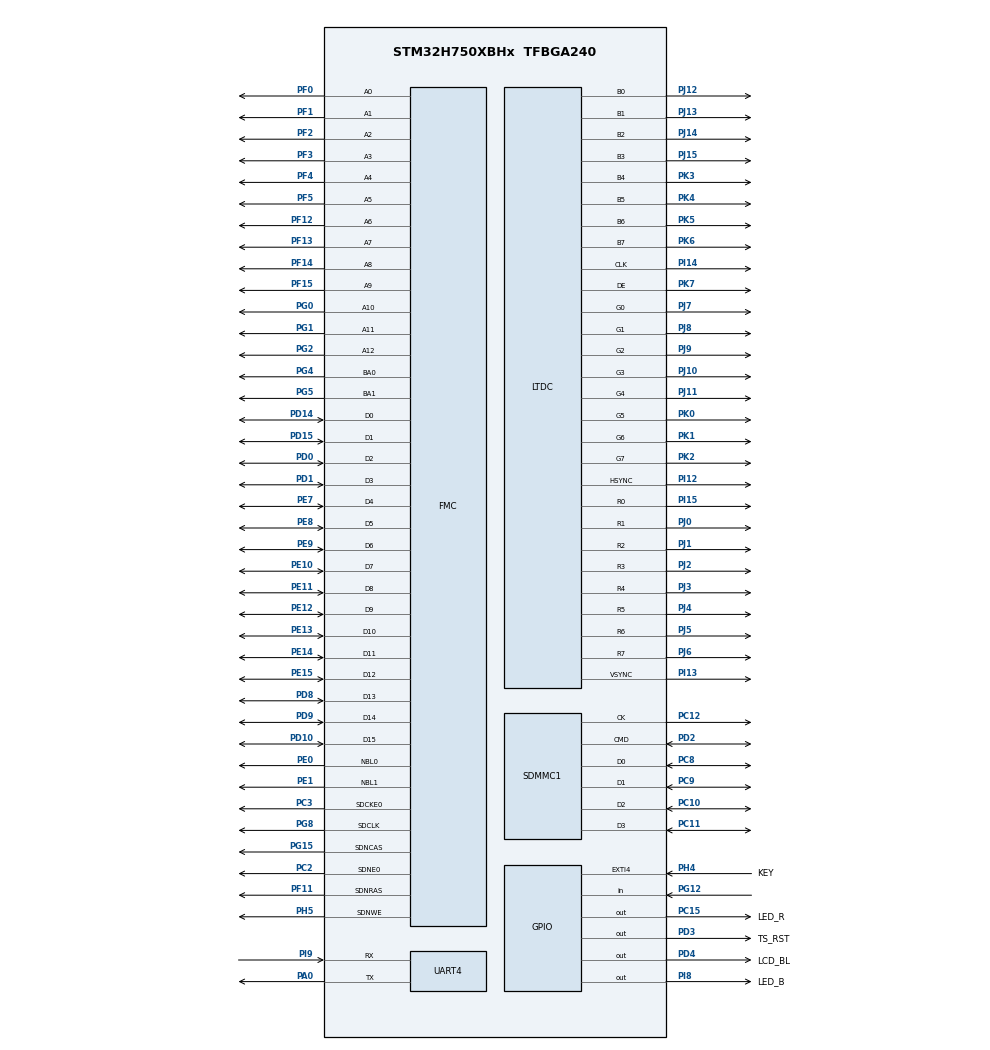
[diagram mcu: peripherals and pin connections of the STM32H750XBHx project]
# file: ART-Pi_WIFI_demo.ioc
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CORTEX_M7.AccessPermission-Cortex_Memory_Protection_Unit_Region0_Settings=MPU_REGION_FULL_ACCESS
CORTEX_M7.AccessPermission-Cortex_Memory_Protection_Unit_Region1_Settings=MPU_REGION_FULL_ACCESS
CORTEX_M7.AccessPermission-Cortex_Memory_Protection_Unit_Region2_Settings=MPU_REGION_FULL_ACCESS
CORTEX_M7.AccessPermission_Spec=MPU_REGION_FULL_ACCESS
CORTEX_M7.BaseAddress-Cortex_Memory_Protection_Unit_Region0_Settings=0x90000000
CORTEX_M7.BaseAddress-Cortex_Memory_Protection_Unit_Region1_Settings=0xC0000000
CORTEX_M7.BaseAddress-Cortex_Memory_Protection_Unit_Region2_Settings=0x24000000
CORTEX_M7.BaseAddress_Spec=0x90000000
CORTEX_M7.CPU_DCache=Enabled
CORTEX_M7.CPU_ICache=Enabled
CORTEX_M7.Enable-Cortex_Memory_Protection_Unit_Region0_Settings=MPU_REGION_ENABLE
CORTEX_M7.Enable-Cortex_Memory_Protection_Unit_Region1_Settings=MPU_REGION_ENABLE
CORTEX_M7.Enable-Cortex_Memory_Protection_Unit_Region2_Settings=MPU_REGION_ENABLE
CORTEX_M7.IsBufferable-Cortex_Memory_Protection_Unit_Region0_Settings=MPU_ACCESS_BUFFERABLE
CORTEX_M7.IsBufferable-Cortex_Memory_Protection_Unit_Region2_Settings=MPU_ACCESS_BUFFERABLE
CORTEX_M7.IsBufferable_Spec=MPU_ACCESS_BUFFERABLE
CORTEX_M7.IsCacheable-Cortex_Memory_Protection_Unit_Region0_Settings=MPU_ACCESS_CACHEABLE
CORTEX_M7.IsCacheable-Cortex_Memory_Protection_Unit_Region1_Settings=MPU_ACCESS_CACHEABLE
CORTEX_M7.IsCacheable-Cortex_Memory_Protection_Unit_Region2_Settings=MPU_ACCESS_CACHEABLE
CORTEX_M7.IsCacheable_Spec=MPU_ACCESS_CACHEABLE
CORTEX_M7.IsShareable_Spec=MPU_ACCESS_NOT_SHAREABLE
CORTEX_M7.MPU_Control=MPU_PRIVILEGED_DEFAULT
CORTEX_M7.Size-Cortex_Memory_Protection_Unit_Region0_Settings=MPU_REGION_SIZE_8MB
CORTEX_M7.Size-Cortex_Memory_Protection_Unit_Region1_Settings=MPU_REGION_SIZE_32MB
CORTEX_M7.Size-Cortex_Memory_Protection_Unit_Region2_Settings=MPU_REGION_SIZE_512KB
CORTEX_M7.Size_Spec=MPU_REGION_SIZE_8MB
CORTEX_M7.TypeExtField-Cortex_Memory_Protection_Unit_Region0_Settings=MPU_TEX_LEVEL1
CORTEX_M7.TypeExtField-Cortex_Memory_Protection_Unit_Region2_Settings=MPU_TEX_LEVEL1
CORTEX_M7.TypeExtField_Spec=MPU_TEX_LEVEL1
DMA2D.ColorMode=DMA2D_OUTPUT_RGB565
DMA2D.Mode=DMA2D_M2M
Dma.Request0=UART4_RX
Dma.Request1=UART4_TX
Dma.UART4_RX.0.Direction=DMA_PERIPH_TO_MEMORY
Dma.UART4_RX.0.EventEnable=DISABLE
Dma.UART4_RX.0.FIFOMode=DMA_FIFOMODE_DISABLE
Dma.UART4_RX.0.Instance=DMA1_Stream0
Dma.UART4_RX.0.MemDataAlignment=DMA_MDATAALIGN_BYTE
Dma.UART4_RX.0.MemInc=DMA_MINC_ENABLE
Dma.UART4_RX.0.Mode=DMA_NORMAL
Dma.UART4_RX.0.PeriphDataAlignment=DMA_PDATAALIGN_BYTE
Dma.UART4_RX.0.PeriphInc=DMA_PINC_DISABLE
Dma.UART4_RX.0.Polarity=HAL_DMAMUX_REQ_GEN_RISING
Dma.UART4_RX.0.Priority=DMA_PRIORITY_LOW
Dma.UART4_RX.0.RequestNumber=1
Dma.UART4_RX.0.SignalID=NONE
Dma.UART4_RX.0.SyncEnable=DISABLE
Dma.UART4_RX.0.SyncPolarity=HAL_DMAMUX_SYNC_NO_EVENT
Dma.UART4_RX.0.SyncRequestNumber=1
Dma.UART4_RX.0.SyncSignalID=NONE
Dma.UART4_TX.1.Direction=DMA_MEMORY_TO_PERIPH
Dma.UART4_TX.1.EventEnable=DISABLE
Dma.UART4_TX.1.FIFOMode=DMA_FIFOMODE_DISABLE
Dma.UART4_TX.1.Instance=DMA1_Stream1
Dma.UART4_TX.1.MemDataAlignment=DMA_MDATAALIGN_BYTE
Dma.UART4_TX.1.MemInc=DMA_MINC_ENABLE
Dma.UART4_TX.1.Mode=DMA_NORMAL
Dma.UART4_TX.1.PeriphDataAlignment=DMA_PDATAALIGN_BYTE
Dma.UART4_TX.1.PeriphInc=DMA_PINC_DISABLE
Dma.UART4_TX.1.Polarity=HAL_DMAMUX_REQ_GEN_RISING
Dma.UART4_TX.1.Priority=DMA_PRIORITY_LOW
Dma.UART4_TX.1.RequestNumber=1
Dma.UART4_TX.1.SignalID=NONE
Dma.UART4_TX.1.SyncEnable=DISABLE
Dma.UART4_TX.1.SyncPolarity=HAL_DMAMUX_SYNC_NO_EVENT
Dma.UART4_TX.1.SyncRequestNumber=1
Dma.UART4_TX.1.SyncSignalID=NONE
FATFS._CODE_PAGE=936
FATFS._FS_EXFAT=1
FATFS._MAX_SS=4096
FATFS._MIN_SS=512
FATFS._USE_LFN=2
FMC.CASLatency1=FMC_SDRAM_CAS_LATENCY_3
FMC.ColumnBitsNumber1=FMC_SDRAM_COLUMN_BITS_NUM_9
FMC.ExitSelfRefreshDelay1=8
FMC.LoadToActiveDelay1=2
FMC.RCDDelay1=2
FMC.RPDelay1=2
FMC.ReadBurst1=FMC_SDRAM_RBURST_ENABLE
FMC.ReadPipeDelay1=FMC_SDRAM_RPIPE_DELAY_1
FMC.RowCycleDelay1=7
FMC.SDClockPeriod1=FMC_SDRAM_CLOCK_PERIOD_2
FMC.SelfRefreshTime1=6
FMC.WriteRecoveryTime1=5
FREERTOS.Tasks01=defaultTask,-3,1024,StartDefaultTask,Default,NULL,Dynamic,NULL,NULL;Debug_task,0,1024,debug_thread,Default,NULL,Dynamic,NULL,NULL;lvgl_task,-2,1024,lvgl_thread,Default,NULL,Dynamic,NULL,NULL;flie_task,0,1024,flie_thread,Default,NULL,Dynamic,NULL,NULL;key_task,-2,512,key_thread,Default,NULL,Dynamic,NULL,NULL;led_task,-2,512,led_thread,Default,NULL,Dynamic,NULL,NULL;main_task,-3,2048,main_thread,Default,NULL,Dynamic,NULL,NULL
FREERTOS.configENABLE_FPU=1
FREERTOS.configTOTAL_HEAP_SIZE=40000
FREERTOS.configUSE_NEWLIB_REENTRANT=1
FREERTOS.configUSE_TICK_HOOK=1
LTDC.ActiveH=600
LTDC.ActiveW=1024
LTDC.Alpha_L0=255
LTDC.Blue_L0=255
LTDC.FBStartAdress_L0=0xC0000000
LTDC.Green_L0=255
LTDC.HBP=140
LTDC.HFP=160
LTDC.HSync=20
LTDC.ImageHeight_L0=600
LTDC.ImageWidth_L0=1024
LTDC.Layers=0
LTDC.PixelFormat_L0=LTDC_PIXEL_FORMAT_RGB565
LTDC.Red_L0=255
LTDC.VBP=20
LTDC.VFP=12
LTDC.VSync=3
LTDC.WindowX1_L0=1024
LTDC.WindowY1_L0=600
Mcu.Family=STM32H7
Mcu.Name=STM32H750XBHx
Mcu.Package=TFBGA240
Mcu.UserConstants=LTDC_BUFF_ADDR,0XC0000000
NVIC.DMA1_Stream0_IRQn=true\:5\:0\:true\:false\:true\:true\:false\:true\:true
NVIC.DMA1_Stream1_IRQn=true\:5\:0\:true\:false\:true\:true\:false\:true\:true
NVIC.DMA2D_IRQn=true\:5\:0\:false\:false\:true\:true\:true\:true\:true
NVIC.EXTI4_IRQn=true\:5\:0\:true\:false\:true\:true\:true\:true\:true
NVIC.LTDC_IRQn=true\:5\:0\:false\:false\:true\:true\:true\:true\:true
NVIC.PriorityGroup=NVIC_PRIORITYGROUP_4
NVIC.SDMMC1_IRQn=true\:5\:0\:false\:false\:true\:true\:true\:true\:true
NVIC.TIM6_DAC_IRQn=true\:15\:0\:false\:false\:true\:false\:false\:true\:true
NVIC.TimeBase=TIM6_DAC_IRQn
NVIC.TimeBaseIP=TIM6
NVIC.UART4_IRQn=true\:5\:0\:false\:false\:true\:true\:true\:true\:true
PA0.Mode=Asynchronous
PA0.Signal=UART4_TX
PA13\ (JTMS/SWDIO).Mode=Serial_Wire
PA13\ (JTMS/SWDIO).Signal=DEBUG_JTMS-SWDIO
PA14\ (JTCK/SWCLK).Mode=Serial_Wire
PA14\ (JTCK/SWCLK).Signal=DEBUG_JTCK-SWCLK
PB6.GPIO_Pu=GPIO_PULLUP
PB6.GPIO_Speed=GPIO_SPEED_FREQ_VERY_HIGH
PB6.Signal=I2C1_SCL
PB7.GPIO_Pu=GPIO_PULLUP
PB7.GPIO_Speed=GPIO_SPEED_FREQ_VERY_HIGH
PB7.Signal=I2C1_SDA
PB8.GPIO_Pu=GPIO_PULLUP
PB8.GPIO_Speed=GPIO_SPEED_FREQ_VERY_HIGH
PB8.Signal=I2C4_SCL
PB9.GPIO_Pu=GPIO_PULLUP
PB9.GPIO_Speed=GPIO_SPEED_FREQ_VERY_HIGH
PB9.Signal=I2C4_SDA
PC10.GPIO_PuPd=GPIO_PULLUP
PC10.Mode=SD_4_bits_Wide_bus
PC10.Signal=SDMMC1_D2
PC11.GPIO_PuPd=GPIO_PULLUP
PC11.Mode=SD_4_bits_Wide_bus
PC11.Signal=SDMMC1_D3
PC12.Mode=SD_4_bits_Wide_bus
PC12.Signal=SDMMC1_CK
PC15-OSC32_OUT\ (OSC32_OUT).GPIO_Label=LED_R
PC15-OSC32_OUT\ (OSC32_OUT).Signal=GPIO_Output
PC2.Mode=SdramChipSelect1_1
PC2.Signal=FMC_SDNE0
PC3.Mode=SdramChipSelect1_1
PC3.Signal=FMC_SDCKE0
PC8.GPIO_PuPd=GPIO_PULLUP
PC8.Mode=SD_4_bits_Wide_bus
PC8.Signal=SDMMC1_D0
PC9.GPIO_PuPd=GPIO_PULLUP
PC9.Mode=SD_4_bits_Wide_bus
PC9.Signal=SDMMC1_D1
PD0.Signal=FMC_D2_DA2
PD1.Signal=FMC_D3_DA3
PD10.Signal=FMC_D15_DA15
PD14.Signal=FMC_D0_DA0
PD15.Signal=FMC_D1_DA1
PD2.GPIO_PuPd=GPIO_PULLUP
PD2.Mode=SD_4_bits_Wide_bus
PD2.Signal=SDMMC1_CMD
PD3.GPIO_Label=TS_RST
PD3.GPIO_Speed=GPIO_SPEED_FREQ_HIGH
PD3.Signal=GPIO_Output
PD4.GPIO_Label=LCD_BL
PD4.GPIO_Speed=GPIO_SPEED_FREQ_VERY_HIGH
PD4.Signal=GPIO_Output
PD8.Signal=FMC_D13_DA13
PD9.Signal=FMC_D14_DA14
PE0.Signal=FMC_NBL0
PE1.Signal=FMC_NBL1
PE10.Signal=FMC_D7_DA7
PE11.Signal=FMC_D8_DA8
PE12.Signal=FMC_D9_DA9
PE13.Signal=FMC_D10_DA10
PE14.Signal=FMC_D11_DA11
PE15.Signal=FMC_D12_DA12
PE7.Signal=FMC_D4_DA4
PE8.Signal=FMC_D5_DA5
PE9.Signal=FMC_D6_DA6
PF0.Signal=FMC_A0
PF1.Signal=FMC_A1
PF11.Signal=FMC_SDNRAS
PF12.Signal=FMC_A6
PF13.Signal=FMC_A7
PF14.Signal=FMC_A8
PF15.Signal=FMC_A9
PF2.Signal=FMC_A2
PF3.Signal=FMC_A3
PF4.Signal=FMC_A4
PF5.Signal=FMC_A5
PG0.Signal=FMC_A10
PG1.Signal=FMC_A11
PG12.GPIO_PuPd=GPIO_PULLUP
PG12.Signal=GPIO_Input
PG15.Signal=FMC_SDNCAS
PG2.Signal=FMC_A12
PG4.Signal=FMC_A14_BA0
PG5.Signal=FMC_A15_BA1
PG8.Signal=FMC_SDCLK
PH0-OSC_IN\ (PH0).Mode=HSE-External-Oscillator
PH0-OSC_IN\ (PH0).Signal=RCC_OSC_IN
PH1-OSC_OUT\ (PH1).Mode=HSE-External-Oscillator
PH1-OSC_OUT\ (PH1).Signal=RCC_OSC_OUT
PH4.GPIO_Label=KEY
PH4.GPIO_ModeDefaultEXTI=GPIO_MODE_IT_FALLING
PH4.GPIO_PuPd=GPIO_PULLUP
PH4.Signal=GPXTI4
PH5.Signal=FMC_SDNWE
PI12.GPIO_Speed=GPIO_SPEED_FREQ_VERY_HIGH
PI12.Mode=RGB888
PI12.Signal=LTDC_HSYNC
PI13.GPIO_Speed=GPIO_SPEED_FREQ_VERY_HIGH
PI13.Mode=RGB888
PI13.Signal=LTDC_VSYNC
PI14.GPIO_Speed=GPIO_SPEED_FREQ_VERY_HIGH
PI14.Mode=RGB888
PI14.Signal=LTDC_CLK
PI15.GPIO_Speed=GPIO_SPEED_FREQ_VERY_HIGH
PI15.Mode=RGB888
PI15.Signal=LTDC_R0
PI8.GPIO_Label=LED_B
PI8.Signal=GPIO_Output
PI9.Mode=Asynchronous
PI9.Signal=UART4_RX
PJ0.GPIO_Speed=GPIO_SPEED_FREQ_VERY_HIGH
PJ0.Mode=RGB888
PJ0.Signal=LTDC_R1
PJ1.GPIO_Speed=GPIO_SPEED_FREQ_VERY_HIGH
PJ1.Mode=RGB888
PJ1.Signal=LTDC_R2
PJ10.GPIO_Speed=GPIO_SPEED_FREQ_VERY_HIGH
PJ10.Mode=RGB888
PJ10.Signal=LTDC_G3
PJ11.GPIO_Speed=GPIO_SPEED_FREQ_VERY_HIGH
PJ11.Mode=RGB888
PJ11.Signal=LTDC_G4
PJ12.GPIO_Speed=GPIO_SPEED_FREQ_VERY_HIGH
PJ12.Mode=RGB888
PJ12.Signal=LTDC_B0
PJ13.GPIO_Speed=GPIO_SPEED_FREQ_VERY_HIGH
PJ13.Mode=RGB888
PJ13.Signal=LTDC_B1
PJ14.GPIO_Speed=GPIO_SPEED_FREQ_VERY_HIGH
PJ14.Mode=RGB888
PJ14.Signal=LTDC_B2
PJ15.GPIO_Speed=GPIO_SPEED_FREQ_VERY_HIGH
PJ15.Mode=RGB888
PJ15.Signal=LTDC_B3
PJ2.GPIO_Speed=GPIO_SPEED_FREQ_VERY_HIGH
PJ2.Mode=RGB888
PJ2.Signal=LTDC_R3
PJ3.GPIO_Speed=GPIO_SPEED_FREQ_VERY_HIGH
PJ3.Mode=RGB888
PJ3.Signal=LTDC_R4
PJ4.GPIO_Speed=GPIO_SPEED_FREQ_VERY_HIGH
PJ4.Mode=RGB888
PJ4.Signal=LTDC_R5
PJ5.GPIO_Speed=GPIO_SPEED_FREQ_VERY_HIGH
PJ5.Mode=RGB888
PJ5.Signal=LTDC_R6
PJ6.GPIO_Speed=GPIO_SPEED_FREQ_VERY_HIGH
PJ6.Mode=RGB888
PJ6.Signal=LTDC_R7
PJ7.GPIO_Speed=GPIO_SPEED_FREQ_VERY_HIGH
PJ7.Mode=RGB888
PJ7.Signal=LTDC_G0
PJ8.GPIO_Speed=GPIO_SPEED_FREQ_VERY_HIGH
PJ8.Mode=RGB888
PJ8.Signal=LTDC_G1
PJ9.GPIO_Speed=GPIO_SPEED_FREQ_VERY_HIGH
PJ9.Mode=RGB888
PJ9.Signal=LTDC_G2
PK0.GPIO_Speed=GPIO_SPEED_FREQ_VERY_HIGH
PK0.Mode=RGB888
PK0.Signal=LTDC_G5
PK1.GPIO_Speed=GPIO_SPEED_FREQ_VERY_HIGH
PK1.Mode=RGB888
PK1.Signal=LTDC_G6
PK2.GPIO_Speed=GPIO_SPEED_FREQ_VERY_HIGH
PK2.Mode=RGB888
PK2.Signal=LTDC_G7
PK3.GPIO_Speed=GPIO_SPEED_FREQ_VERY_HIGH
PK3.Mode=RGB888
PK3.Signal=LTDC_B4
PK4.GPIO_Speed=GPIO_SPEED_FREQ_VERY_HIGH
PK4.Mode=RGB888
PK4.Signal=LTDC_B5
PK5.GPIO_Speed=GPIO_SPEED_FREQ_VERY_HIGH
PK5.Mode=RGB888
PK5.Signal=LTDC_B6
PK6.GPIO_Speed=GPIO_SPEED_FREQ_VERY_HIGH
PK6.Mode=RGB888
PK6.Signal=LTDC_B7
PK7.GPIO_Speed=GPIO_SPEED_FREQ_VERY_HIGH
PK7.Mode=RGB888
PK7.Signal=LTDC_DE
ProjectManager.HeapSize=0xFFFF
ProjectManager.StackSize=0xFFFF
ProjectManager.TargetToolchain=STM32CubeIDE
RCC.ADCFreq_Value=50390625
RCC.APB1Freq_Value=120000000
RCC.APB2Freq_Value=120000000
RCC.APB3Freq_Value=120000000
RCC.APB4Freq_Value=120000000
RCC.CortexFreq_Value=480000000
RCC.D1PPRE=RCC_APB3_DIV2
RCC.D2PPRE1=RCC_APB1_DIV2
RCC.D2PPRE2=RCC_APB2_DIV2
RCC.D3PPRE=RCC_APB4_DIV2
RCC.DIVM1=5
RCC.DIVM3=1
RCC.DIVN1=192
RCC.DIVN3=12
RCC.DIVQ1=4
RCC.DIVQ2=1
RCC.DIVR3=5
RCC.HCLKFreq_Value=240000000
RCC.HPRE=RCC_HCLK_DIV2
RCC.PLL3FRACN=0
RCC.PLLFRACN=0
RCC.PLLSourceVirtual=RCC_PLLSOURCE_HSE
RCC.PWR_Regulator_Voltage_Scale=PWR_REGULATOR_VOLTAGE_SCALE0
RCC.ProductRev=revV
RCC.SYSCLKFreq_VALUE=480000000
RCC.SYSCLKSource=RCC_SYSCLKSOURCE_PLLCLK
RCC.USBFreq_Value=240000000
SDMMC1.ClockDiv=6
SH.FMC_A0.0=FMC_A0,13b-sda1
SH.FMC_A1.0=FMC_A1,13b-sda1
SH.FMC_A10.0=FMC_A10,13b-sda1
SH.FMC_A11.0=FMC_A11,13b-sda1
SH.FMC_A12.0=FMC_A12,13b-sda1
SH.FMC_A14_BA0.0=FMC_BA0,FourSdramBanks1
SH.FMC_A15_BA1.0=FMC_BA1,FourSdramBanks1
SH.FMC_A2.0=FMC_A2,13b-sda1
SH.FMC_A3.0=FMC_A3,13b-sda1
SH.FMC_A4.0=FMC_A4,13b-sda1
SH.FMC_A5.0=FMC_A5,13b-sda1
SH.FMC_A6.0=FMC_A6,13b-sda1
SH.FMC_A7.0=FMC_A7,13b-sda1
SH.FMC_A8.0=FMC_A8,13b-sda1
SH.FMC_A9.0=FMC_A9,13b-sda1
SH.FMC_D0_DA0.0=FMC_D0,sd-16b-d1
SH.FMC_D10_DA10.0=FMC_D10,sd-16b-d1
SH.FMC_D11_DA11.0=FMC_D11,sd-16b-d1
SH.FMC_D12_DA12.0=FMC_D12,sd-16b-d1
SH.FMC_D13_DA13.0=FMC_D13,sd-16b-d1
SH.FMC_D14_DA14.0=FMC_D14,sd-16b-d1
SH.FMC_D15_DA15.0=FMC_D15,sd-16b-d1
SH.FMC_D1_DA1.0=FMC_D1,sd-16b-d1
SH.FMC_D2_DA2.0=FMC_D2,sd-16b-d1
SH.FMC_D3_DA3.0=FMC_D3,sd-16b-d1
SH.FMC_D4_DA4.0=FMC_D4,sd-16b-d1
SH.FMC_D5_DA5.0=FMC_D5,sd-16b-d1
SH.FMC_D6_DA6.0=FMC_D6,sd-16b-d1
SH.FMC_D7_DA7.0=FMC_D7,sd-16b-d1
SH.FMC_D8_DA8.0=FMC_D8,sd-16b-d1
SH.FMC_D9_DA9.0=FMC_D9,sd-16b-d1
SH.FMC_NBL0.0=FMC_NBL0,Sd2ByteEnable1
SH.FMC_NBL1.0=FMC_NBL1,Sd2ByteEnable1
SH.FMC_SDCLK.0=FMC_SDCLK,13b-sda1
SH.FMC_SDNCAS.0=FMC_SDNCAS,13b-sda1
SH.FMC_SDNRAS.0=FMC_SDNRAS,13b-sda1
SH.FMC_SDNWE.0=FMC_SDNWE,13b-sda1
VP_DMA2D_VS_DMA2D.Mode=DMA2D_Activate
VP_FATFS_VS_SDIO.Mode=SDIO
VP_FREERTOS_VS_CMSIS_V1.Mode=CMSIS_V1
VP_SYS_VS_tim6.Mode=TIM6
board=custom

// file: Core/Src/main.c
/* USER CODE BEGIN Header */
/**
  ******************************************************************************
  * @file           : main.c
  * @brief          : Main program body
  ******************************************************************************
  * @attention
  *
  * Copyright (c) 2023 STMicroelectronics.
  * All rights reserved.
  *
  * This software is licensed under terms that can be found in the LICENSE file
  * in the root directory of this software component.
  * If no LICENSE file comes with this software, it is provided AS-IS.
  *
  ******************************************************************************
  */
/* USER CODE END Header */
#include "main.h"
#include "cmsis_os.h"
#include "dma.h"
#include "dma2d.h"
#include "fatfs.h"
#include "ltdc.h"
#include "sdmmc.h"
#include "usart.h"
#include "gpio.h"
#include "fmc.h"

/* USER CODE BEGIN Includes */
#include "sdram_fmc_drv.h"
#include "SD_use.h"
#include "touch.h"
#include "user_time.h"
#include "user_i2c_gpio.h"
/* USER CODE END Includes */

void SystemClock_Config(void);
static void MPU_Config(void);
void MX_FREERTOS_Init(void);

int main(void)
{

    /* MPU Configuration--------------------------------------------------------*/
    MPU_Config();

    /* Enable the CPU Cache */

    /* Enable I-Cache---------------------------------------------------------*/
    SCB_EnableICache();

    /* Enable D-Cache---------------------------------------------------------*/
    SCB_EnableDCache();

    /* MCU Configuration--------------------------------------------------------*/

    /* Reset of all peripherals, Initializes the Flash interface and the Systick. */
    HAL_Init();

    /* Configure the system clock */
    SystemClock_Config();

    /* Initialize all configured peripherals */
    MX_GPIO_Init();
    MX_DMA_Init();
    MX_UART4_Init();
    MX_FMC_Init();
    MX_DMA2D_Init();
    MX_LTDC_Init();
    MX_SDMMC1_SD_Init();
    MX_FATFS_Init();
    /* USER CODE BEGIN 2 */
    /***********************init device use*****************************************/
    SDRAM_Init();
    bsp_InitI2C();
    /************************init Edit *********************************************/
    LCD_BL_GPIO_Port->ODR|=LCD_BL_Pin;
    LTDC_Init();
    Touch_Init();
    LTDC_Clear(WHITE);
    /* USER CODE END 2 */

    /* Call init function for freertos objects (in cmsis_os2.c) */
    MX_FREERTOS_Init();

    /* Start scheduler */
    osKernelStart();

    /* We should never get here as control is now taken by the scheduler */

    /* Infinite loop */
    while (1)
    {

        /* USER CODE BEGIN 3 */
        GPIOC->ODR^=GPIO_PIN_15;
        HAL_Delay(100);

    }
    /* USER CODE END 3 */
}

void SystemClock_Config(void)
{
    RCC_OscInitTypeDef RCC_OscInitStruct = {0};
    RCC_ClkInitTypeDef RCC_ClkInitStruct = {0};

    /** Supply configuration update enable
    */
    HAL_PWREx_ConfigSupply(PWR_LDO_SUPPLY);

    /** Configure the main internal regulator output voltage
    */
    __HAL_PWR_VOLTAGESCALING_CONFIG(PWR_REGULATOR_VOLTAGE_SCALE1);

    while(!__HAL_PWR_GET_FLAG(PWR_FLAG_VOSRDY)) {}

    __HAL_RCC_SYSCFG_CLK_ENABLE();
    __HAL_PWR_VOLTAGESCALING_CONFIG(PWR_REGULATOR_VOLTAGE_SCALE0);

    while(!__HAL_PWR_GET_FLAG(PWR_FLAG_VOSRDY)) {}

    /** Initializes the RCC Oscillators according to the specified parameters
    * in the RCC_OscInitTypeDef structure.
    */
    RCC_OscInitStruct.OscillatorType = RCC_OSCILLATORTYPE_HSE;
    RCC_OscInitStruct.HSEState = RCC_HSE_ON;
    RCC_OscInitStruct.PLL.PLLState = RCC_PLL_ON;
    RCC_OscInitStruct.PLL.PLLSource = RCC_PLLSOURCE_HSE;
    RCC_OscInitStruct.PLL.PLLM = 5;
    RCC_OscInitStruct.PLL.PLLN = 192;
    RCC_OscInitStruct.PLL.PLLP = 2;
    RCC_OscInitStruct.PLL.PLLQ = 4;
    RCC_OscInitStruct.PLL.PLLR = 2;
    RCC_OscInitStruct.PLL.PLLRGE = RCC_PLL1VCIRANGE_2;
    RCC_OscInitStruct.PLL.PLLVCOSEL = RCC_PLL1VCOWIDE;
    RCC_OscInitStruct.PLL.PLLFRACN = 0;
    if (HAL_RCC_OscConfig(&RCC_OscInitStruct) != HAL_OK)
    {
        Error_Handler();
    }

    /** Initializes the CPU, AHB and APB buses clocks
    */
    RCC_ClkInitStruct.ClockType = RCC_CLOCKTYPE_HCLK|RCC_CLOCKTYPE_SYSCLK
                                  |RCC_CLOCKTYPE_PCLK1|RCC_CLOCKTYPE_PCLK2
                                  |RCC_CLOCKTYPE_D3PCLK1|RCC_CLOCKTYPE_D1PCLK1;
    RCC_ClkInitStruct.SYSCLKSource = RCC_SYSCLKSOURCE_PLLCLK;
    RCC_ClkInitStruct.SYSCLKDivider = RCC_SYSCLK_DIV1;
    RCC_ClkInitStruct.AHBCLKDivider = RCC_HCLK_DIV2;
    RCC_ClkInitStruct.APB3CLKDivider = RCC_APB3_DIV2;
    RCC_ClkInitStruct.APB1CLKDivider = RCC_APB1_DIV2;
    RCC_ClkInitStruct.APB2CLKDivider = RCC_APB2_DIV2;
    RCC_ClkInitStruct.APB4CLKDivider = RCC_APB4_DIV2;

    if (HAL_RCC_ClockConfig(&RCC_ClkInitStruct, FLASH_LATENCY_4) != HAL_OK)
    {
        Error_Handler();
    }
}

/* MPU Configuration */

void MPU_Config(void)
{
    MPU_Region_InitTypeDef MPU_InitStruct = {0};

    /* Disables the MPU */
    HAL_MPU_Disable();

    /** Initializes and configures the Region and the memory to be protected
    */
    MPU_InitStruct.Enable = MPU_REGION_ENABLE;
    MPU_InitStruct.Number = MPU_REGION_NUMBER0;
    MPU_InitStruct.BaseAddress = 0x90000000;
    MPU_InitStruct.Size = MPU_REGION_SIZE_8MB;
    MPU_InitStruct.SubRegionDisable = 0x0;
    MPU_InitStruct.TypeExtField = MPU_TEX_LEVEL1;
    MPU_InitStruct.AccessPermission = MPU_REGION_FULL_ACCESS;
    MPU_InitStruct.DisableExec = MPU_INSTRUCTION_ACCESS_ENABLE;
    MPU_InitStruct.IsShareable = MPU_ACCESS_NOT_SHAREABLE;
    MPU_InitStruct.IsCacheable = MPU_ACCESS_CACHEABLE;
    MPU_InitStruct.IsBufferable = MPU_ACCESS_BUFFERABLE;

    HAL_MPU_ConfigRegion(&MPU_InitStruct);

    /** Initializes and configures the Region and the memory to be protected
    */
    MPU_InitStruct.Number = MPU_REGION_NUMBER1;
    MPU_InitStruct.BaseAddress = 0xC0000000;
    MPU_InitStruct.Size = MPU_REGION_SIZE_32MB;
    MPU_InitStruct.TypeExtField = MPU_TEX_LEVEL0;
    MPU_InitStruct.IsBufferable = MPU_ACCESS_NOT_BUFFERABLE;

    HAL_MPU_ConfigRegion(&MPU_InitStruct);

    /** Initializes and configures the Region and the memory to be protected
    */
    MPU_InitStruct.Number = MPU_REGION_NUMBER2;
    MPU_InitStruct.BaseAddress = 0x24000000;
    MPU_InitStruct.Size = MPU_REGION_SIZE_512KB;
    MPU_InitStruct.TypeExtField = MPU_TEX_LEVEL1;
    MPU_InitStruct.IsBufferable = MPU_ACCESS_BUFFERABLE;

    HAL_MPU_ConfigRegion(&MPU_InitStruct);
    /* Enables the MPU */
    HAL_MPU_Enable(MPU_PRIVILEGED_DEFAULT);

}

void HAL_TIM_PeriodElapsedCallback(TIM_HandleTypeDef *htim)
{
    if (htim->Instance == TIM6) {
        HAL_IncTick();
    }
}

void Error_Handler(void)
{
    /* USER CODE BEGIN Error_Handler_Debug */
    /* Bsp can add his own implementation to report the HAL error return state */
    __disable_irq();
    while (1)
    {
    }
    /* USER CODE END Error_Handler_Debug */
}

#ifdef  USE_FULL_ASSERT
/**
  * @brief  Reports the name of the source file and the source line number
  *         where the assert_param error has occurred.
  * @param  file: pointer to the source file name
  * @param  line: assert_param error line source number
  * @retval None
  */
void assert_failed(uint8_t *file, uint32_t line)
{
  /* USER CODE BEGIN 6 */
  /* Bsp can add his own implementation to report the file name and line number,
     ex: printf("Wrong parameters value: file %s on line %d\r\n", file, line) */
  /* USER CODE END 6 */
}
#endif /* USE_FULL_ASSERT */

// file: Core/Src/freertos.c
/* USER CODE BEGIN Header */
/**
  ******************************************************************************
  * File Name          : freertos.c
  * Description        : Code for freertos applications
  ******************************************************************************
  * @attention
  *
  * Copyright (c) 2024 STMicroelectronics.
  * All rights reserved.
  *
  * This software is licensed under terms that can be found in the LICENSE file
  * in the root directory of this software component.
  * If no LICENSE file comes with this software, it is provided AS-IS.
  *
  ******************************************************************************
  */
/* USER CODE END Header */

#include "FreeRTOS.h"
#include "task.h"
#include "main.h"
#include "cmsis_os.h"

/* USER CODE BEGIN Includes */
#include "SD_use.h"
#include "sdmmc.h"
#include "touch.h"
#include "lvgl.h"
#include "../LVGL/porting/lv_port_disp.h"
#include "../LVGL/porting/lv_port_indev.h"
#include "benchmark/lv_demo_benchmark.h"
#include "../../App/inc/init_task.h"
/* USER CODE END Includes */

osThreadId defaultTaskHandle;
osThreadId Debug_taskHandle;
osThreadId lvgl_taskHandle;
osThreadId flie_taskHandle;
osThreadId key_taskHandle;
osThreadId led_taskHandle;
osThreadId main_taskHandle;

void StartDefaultTask(void const * argument);
void debug_thread(void const * argument);
void lvgl_thread(void const * argument);
void flie_thread(void const * argument);
void key_thread(void const * argument);
void led_thread(void const * argument);
void main_thread(void const * argument);

void MX_FREERTOS_Init(void); /* (MISRA C 2004 rule 8.1) */

/* GetIdleTaskMemory prototype (linked to static allocation support) */
void vApplicationGetIdleTaskMemory( StaticTask_t **ppxIdleTaskTCBBuffer, StackType_t **ppxIdleTaskStackBuffer, uint32_t *pulIdleTaskStackSize );

/* Hook prototypes */
void vApplicationTickHook(void);

/* USER CODE BEGIN 3 */
__weak void vApplicationTickHook( void )
{
    /* This function will be called by each tick interrupt if
    configUSE_TICK_HOOK is set to 1 in FreeRTOSConfig.h. Bsp code can be
    added here, but the tick hook is called from an interrupt context, so
    code must not attempt to block, and only the interrupt safe FreeRTOS API
    functions can be used (those that end in FromISR()). */
    lv_tick_inc(1);
}
/* USER CODE END 3 */

/* USER CODE BEGIN GET_IDLE_TASK_MEMORY */
static StaticTask_t xIdleTaskTCBBuffer;
static StackType_t xIdleStack[configMINIMAL_STACK_SIZE];

void vApplicationGetIdleTaskMemory( StaticTask_t **ppxIdleTaskTCBBuffer, StackType_t **ppxIdleTaskStackBuffer, uint32_t *pulIdleTaskStackSize )
{
    *ppxIdleTaskTCBBuffer = &xIdleTaskTCBBuffer;
    *ppxIdleTaskStackBuffer = &xIdleStack[0];
    *pulIdleTaskStackSize = configMINIMAL_STACK_SIZE;
    /* place for user code */
}
/* USER CODE END GET_IDLE_TASK_MEMORY */

void MX_FREERTOS_Init(void) {

    /* Create the thread(s) */
    /* definition and creation of defaultTask */
    osThreadDef(defaultTask, StartDefaultTask, osPriorityIdle, 0, 1024);
    defaultTaskHandle = osThreadCreate(osThread(defaultTask), NULL);

//    /* definition and creation of Debug_task */
//    osThreadDef(Debug_task, debug_thread, osPriorityNormal, 0, 1024);
//    Debug_taskHandle = osThreadCreate(osThread(Debug_task), NULL);
//
//    /* definition and creation of lvgl_task */
//    osThreadDef(lvgl_task, lvgl_thread, osPriorityLow, 0, 1024);
//    lvgl_taskHandle = osThreadCreate(osThread(lvgl_task), NULL);
//
//    /* definition and creation of flie_task */
//    osThreadDef(flie_task, flie_thread, osPriorityNormal, 0, 1024);
//    flie_taskHandle = osThreadCreate(osThread(flie_task), NULL);

    /* definition and creation of key_task */
    osThreadDef(key_task, key_thread, osPriorityLow, 0, 512);
    key_taskHandle = osThreadCreate(osThread(key_task), NULL);

    /* definition and creation of led_task */
    osThreadDef(led_task, led_thread, osPriorityLow, 0, 512);
    led_taskHandle = osThreadCreate(osThread(led_task), NULL);

    /* definition and creation of main_task */
    osThreadDef(main_task, main_thread, osPriorityIdle, 0, 2048);
    main_taskHandle = osThreadCreate(osThread(main_task), NULL);

    /* USER CODE BEGIN RTOS_THREADS */
    /* add threads, ... */
    wifi_init();
    /* USER CODE END RTOS_THREADS */

}

void StartDefaultTask(void const * argument)
{
    for(;;)
    {
        osDelay(1);
    }
}

void debug_thread(void const * argument)
{
    for(;;)
    {
        osDelay(1);
    }
}

void lvgl_thread(void const * argument)
{
    /* USER CODE BEGIN lvgl_thread */
    /* Infinite loop */
    lv_init();
    lv_port_disp_init();
    lv_port_indev_init();

    lv_demo_benchmark();

    for(;;)
    {
        lv_task_handler();
        osDelay(1);
    }
    /* USER CODE END lvgl_thread */
}

void flie_thread(void const * argument)
{
    for(;;)
    {
        osDelay(1);
    }
}

void key_thread(void const * argument)
{
    /* USER CODE BEGIN key_thread */
    /* Infinite loop */

    for(;;)
    {
        osDelay(300);
    }
    /* USER CODE END key_thread */
}

void led_thread(void const * argument)
{
    /* USER CODE BEGIN led_thread */
    LED_R_GPIO_Port->ODR |= LED_R_Pin;
    LED_B_GPIO_Port->ODR |= LED_B_Pin;
    /* Infinite loop */
    for(;;)
    {
        osDelay(500);
        LED_B_GPIO_Port->ODR ^= LED_B_Pin;
    }
    /* USER CODE END led_thread */
}

void main_thread(void const * argument)
{
    for(;;)
    {
        osDelay(1);
    }
}
